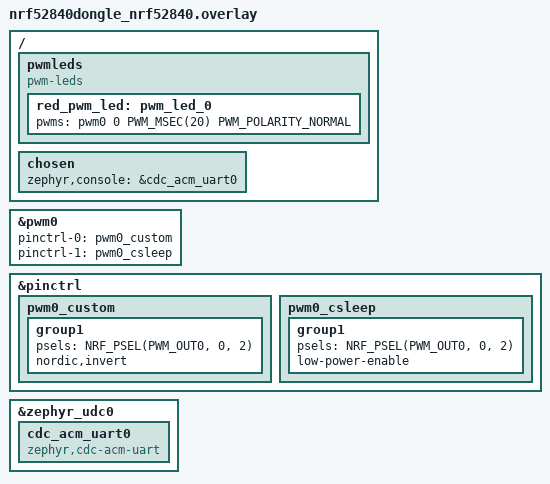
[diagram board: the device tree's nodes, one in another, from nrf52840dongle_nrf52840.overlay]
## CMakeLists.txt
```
cmake_minimum_required(VERSION 3.20.0)
find_package(Zephyr REQUIRED HINTS $ENV{ZEPHYR_BASE})

project(final_pwm)

target_sources(app PRIVATE src/main.c)

# Custom files and folders
target_sources(app PRIVATE
    src/custom_files/serwo_control.c;
    src/custom_files/remote.c
)
zephyr_library_include_directories(src/custom_files)
```

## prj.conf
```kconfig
# Configure PWM
CONFIG_PWM=y
CONFIG_GPIO=y

# Configure Bluetooth
CONFIG_BT=y
CONFIG_BT_PERIPHERAL=y
CONFIG_BT_DEVICE_NAME="Sterowanie_klapa_BLE"
CONFIG_BT_DEVICE_APPEARANCE=0
CONFIG_BT_MAX_CONN=1
CONFIG_BT_LL_SOFTDEVICE=y

CONFIG_ASSERT=y

# USB
CONFIG_USB_DEVICE_STACK=y
CONFIG_USB_DEVICE_PRODUCT="Sterownik Klapy USB"
CONFIG_USB_DEVICE_PID=0x0004
CONFIG_USB_DEVICE_INITIALIZE_AT_BOOT=n

CONFIG_SERIAL=y
CONFIG_CONSOLE=y
CONFIG_UART_CONSOLE=y
CONFIG_UART_LINE_CTRL=y
```

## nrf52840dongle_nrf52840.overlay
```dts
// To get started, press Ctrl+Space to bring up the completion menu and view the available nodes.

// You can also use the buttons in the sidebar to perform actions on nodes.
// Actions currently available include:

// * Enabling / disabling the node
// * Adding the bus to a bus
// * Removing the node
// * Connecting ADC channels

// For more help, browse the DeviceTree documentation at https://docs.zephyrproject.org/latest/guides/dts/index.html
// You can also visit the nRF DeviceTree extension documentation at https://nrfconnect.github.io/vscode-nrf-connect/devicetree/nrfdevicetree.html



&pwm0 {
    status = "okay";
    pinctrl-0 = <&pwm0_custom>;
    pinctrl-1 = <&pwm0_csleep>;
    pinctrl-names = "default", "sleep";
};

&pinctrl {
    pwm0_custom: pwm0_custom {
        group1 {
            psels = <NRF_PSEL(PWM_OUT0, 0, 2)>; //0.02 pin
            nordic,invert;
        };
    };

    pwm0_csleep: pwm0_csleep {
        group1 {
            psels = <NRF_PSEL(PWM_OUT0, 0, 2)>; //0.02 pin
            low-power-enable;
        };
    };
};

/{
    pwmleds {
        compatible = "pwm-leds";
        red_pwm_led: pwm_led_0 {
            pwms = <&pwm0 0 PWM_MSEC(20) PWM_POLARITY_NORMAL>;
        };
    };
};


//USB SERIAL
/ {
	chosen {
		zephyr,console = &cdc_acm_uart0;
	};
};

&zephyr_udc0 {
	cdc_acm_uart0: cdc_acm_uart0 {
		compatible = "zephyr,cdc-acm-uart";
	};
};
```

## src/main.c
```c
#include <zephyr/drivers/pwm.h>
#include <zephyr/device.h>
#include <zephyr/devicetree.h>
#include <zephyr/drivers/gpio.h>
#include <zephyr/drivers/uart.h>

#include <zephyr/kernel.h>
#include <zephyr/logging/log.h>
#include "serwo_control.h"

#include "remote.h"

static struct bt_conn *current_conn;

/* LEDs, BUTTON, USB*/
#define LED0_NODE	DT_ALIAS(led0)
static const struct gpio_dt_spec led_button = GPIO_DT_SPEC_GET(LED0_NODE, gpios);

#define LED1_NODE	DT_ALIAS(led1_blue)
static const struct gpio_dt_spec led_bluetooth = GPIO_DT_SPEC_GET(LED1_NODE, gpios);

#define SW0_NODE	DT_ALIAS(sw0)
static const struct gpio_dt_spec button = GPIO_DT_SPEC_GET(SW0_NODE, gpios);

const struct device *const dev = DEVICE_DT_GET(DT_CHOSEN(zephyr_console));
uint32_t dtr = 0;

/* Declarations */
#define SLEEP_TIME_MS   10*60*1000 /*the sleep time 10 minutes  */

volatile int serwo_angle = 90;

void on_connected(struct bt_conn *conn, uint8_t err);
void on_disconnected(struct bt_conn *conn, uint8_t reason);
void on_notif_changed(enum bt_button_notifications_enabled status);
void on_data_received(struct bt_conn *conn, const uint8_t *const data, uint16_t len);

static struct gpio_callback button_cb_data;

struct bt_conn_cb bluetooth_callbacks = {
    .connected      = on_connected,
    .disconnected   = on_disconnected,
};

struct bt_remote_service_cb remote_callbacks = {
	.notif_changed = on_notif_changed,
    .data_received = on_data_received,
};

/* Callbacks */

void on_data_received(struct bt_conn *conn, const uint8_t *const data, uint16_t len)
{
    uint8_t temp_str[len+1];
    memcpy(temp_str, data, len);
    temp_str[len] = 0x00;

	gpio_pin_toggle_dt(&led_button);
    printk("Received data on conn %p. Len: %d\n", (void *)conn, len);
	printk("Data: %"PRIu8"\n", temp_str[0]);

    //mapowanie na potrzeby otrzymania wartosci uint32_t
	//1 000 000ms/65535 = 15.2590218967
	//uint32_t temp = (uint32_t)data[0]*16;

	serwo_angle=(temp_str[0]);
	set_pwm_value(temp_str[0]); //dla ble
	set_serwo_angle(temp_str[0]);
}

void on_notif_changed(enum bt_button_notifications_enabled status)
{
    if (status == BT_BUTTON_NOTIFICATIONS_ENABLED) {
        printk("Notifications enabled (on_notif_changed)\n");
    } else {
        printk("Notifications disabled (on_notif_changed)\n");
    }
}

void on_connected(struct bt_conn *conn, uint8_t err)
{
    if (err) {
        printk("connection failed, err %d\n", err);
    }
    printk("Connected to central\n");
    current_conn = bt_conn_ref(conn);
    gpio_pin_set_dt(&led_bluetooth,1); //dioda niebieska swieci
}

void on_disconnected(struct bt_conn *conn, uint8_t reason)
{
	printk("Disconnected (reason: %d)\n", reason);
	gpio_pin_set_dt(&led_bluetooth,0); //dioda niebieska gasnie
	if(current_conn) {
		bt_conn_unref(current_conn);
		current_conn = NULL;
	}
}

void button_pressed(const struct device *dev, struct gpio_callback *cb, uint32_t pins)
{
    gpio_pin_toggle_dt(&led_button);
	serwo_angle+=20; //+0,2ms

    if (serwo_angle > 180){
		serwo_angle = 0;
	}
        
	printk("BUTTON pwm: %"PRIu32"\n", serwo_angle);

    set_serwo_angle(serwo_angle);
	set_pwm_value(serwo_angle); //dla ble
	send_pwm_notification(current_conn, serwo_angle);
}

/* Configurations */
int leds_usb_button_init(){
	int ret=0;

	//USB
	if (usb_enable(NULL)) {
        return -1;
	}
	//bez while bo bedziemy czekac w nieskonczonosc jezeli nie wlaczymy serial monitora
	//while (!dtr) {
        uart_line_ctrl_get(dev, UART_LINE_CTRL_DTR, &dtr);
        k_sleep(K_MSEC(1000));
	//}
	printk("Sterownik klapy. Inicjalizacja...\n");

	//LED BLUETOOTH
	if (!device_is_ready(led_bluetooth.port)) {
		return -1;
	}
	ret = gpio_pin_configure_dt(&led_bluetooth, GPIO_OUTPUT_ACTIVE);
	if (ret != 0) {
		return -1;
	}
	gpio_pin_set_dt(&led_bluetooth,0); //0 to wylaczona

    //LED BUTTON
	if (!device_is_ready(led_button.port)) {
		return -1;
	}
	ret = gpio_pin_configure_dt(&led_button, GPIO_OUTPUT_ACTIVE);
	if (ret < 0) {
		return -1;
	}
	gpio_pin_set_dt(&led_button,1); //1 to wlaczona
	
	//BUTTON
	if (!device_is_ready(button.port)) {
		return -1;
	}
	ret = gpio_pin_configure_dt(&button, GPIO_INPUT);
	if (ret < 0) {
		return -1;
	}
	/* STEP 3 - Configure the interrupt on the button's pin */
	ret = gpio_pin_interrupt_configure_dt(&button, GPIO_INT_EDGE_TO_ACTIVE );

	/* STEP 6 - Initialize the static struct gpio_callback variable   */
    gpio_init_callback(&button_cb_data, button_pressed, BIT(button.pin)); 	
	
	/* STEP 7 - Add the callback function by calling gpio_add_callback()   */
	gpio_add_callback(button.port, &button_cb_data);
	
	return ret;
}

int main(void)
{
    int err=0;
	err = leds_usb_button_init();
	err = serwo_init();
    err = bluetooth_init(&bluetooth_callbacks,&remote_callbacks);

	//test
	set_battery_value(0x2233);

    if (err) {
        printk("Init failed (err %d)\n", err);
    }

	printk("Poprawnie uruchomiono! %s\n", CONFIG_BOARD);

    for (;;) {
        k_msleep(SLEEP_TIME_MS);
    }
}
```
